VERSION ""

NS_ :

BS_:

BU_: BCM Engine FLR Gateway

BO_ 100 BCM_Status: 8 BCM
 SG_ BCM_DoorLockFL : 0|1@1+ (1,0) [0|1] "" Gateway
 SG_ BCM_DoorLockFR : 1|1@1+ (1,0) [0|1] "" Gateway
 SG_ BCM_DoorLockRL : 2|1@1+ (1,0) [0|1] "" Gateway
 SG_ BCM_DoorLockRR : 3|1@1+ (1,0) [0|1] "" Gateway
 SG_ BCM_TrunkStatus : 4|1@1+ (1,0) [0|1] "" Gateway
 SG_ BCM_HazardLight : 5|1@1+ (1,0) [0|1] "" Gateway
 SG_ BCM_LowBeam : 6|1@1+ (1,0) [0|1] "" Gateway
 SG_ BCM_HighBeam : 7|1@1+ (1,0) [0|1] "" Gateway
 SG_ BCM_BatteryVoltage : 8|12@1+ (0.01,0) [0|40.95] "V" Gateway
 SG_ BCM_InteriorTemp : 20|8@1+ (1,-40) [-40|215] "C" Gateway
 SG_ BCM_Odometer M : 32|4@1+ (1,0) [0|15] "" Gateway
 SG_ BCM_TripA m1 : 36|12@1+ (0.1,0) [0|409.5] "km" Gateway
 SG_ BCM_TripB m2 : 36|12@1+ (0.1,0) [0|409.5] "km" Gateway
 SG_ BCM_FuelLevel m3 : 36|8@1+ (0.4,0) [0|102] "L" Gateway

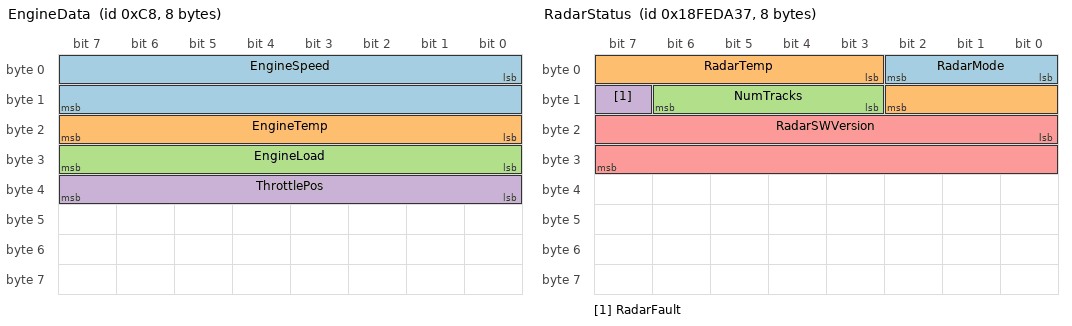
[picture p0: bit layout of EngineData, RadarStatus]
BO_ 200 EngineData: 8 Engine
 SG_ EngineSpeed : 0|16@1+ (0.25,0) [0|16383.75] "rpm" BCM
 SG_ EngineTemp : 16|8@1+ (1,-40) [-40|215] "C" BCM
 SG_ EngineLoad : 24|8@1+ (0.392157,0) [0|100] "%" BCM
 SG_ ThrottlePos : 32|8@1+ (0.392157,0) [0|100] "%" BCM

BO_ 0x18FEDA27 RadarTrack: 8 FLR
 SG_ Track_ID : 0|8@1+ (1,0) [0|255] "" Gateway
 SG_ Track_Dist : 8|12@1+ (0.1,0) [0|409.5] "m" Gateway
 SG_ Track_Vrel : 20|12@1+ (0.01,-20) [-20|20.47] "m/s" Gateway
 SG_ Track_Angle : 32|12@1+ (0.1,-90) [-90|90] "deg" Gateway
 SG_ Track_Status M : 44|2@1+ (1,0) [0|3] "" Gateway
 SG_ Track_RCS m1 : 46|8@1+ (0.5,-10) [-10|117] "dBm" Gateway
 SG_ Track_Lane m2 : 46|3@1+ (1,0) [0|7] "" Gateway
 SG_ Track_Accel m3 : 46|10@1+ (0.01,-5) [-5|5.11] "m/s2" Gateway

BO_ 0x18FEDA37 RadarStatus: 8 FLR
 SG_ RadarMode : 0|3@1+ (1,0) [0|7] "" Gateway
 SG_ RadarTemp : 3|8@1+ (1,-40) [-40|215] "C" Gateway
 SG_ NumTracks : 11|4@1+ (1,0) [0|15] "" Gateway
 SG_ RadarFault : 15|1@1+ (1,0) [0|1] "" Gateway
 SG_ RadarSWVersion : 16|16@1+ (1,0) [0|65535] "" Gateway

BO_ 0x3E8 DiagRequest: 8 Gateway
 SG_ DiagData : 0|64@1+ (1,0) [0|0] "" BCM

BO_ 0x3E9 DiagResponse: 8 BCM
 SG_ DiagData : 0|64@1+ (1,0) [0|0] "" Gateway

VAL_ 100 BCM_DoorLockFL 0 "Locked" 1 "Unlocked" ;
VAL_ 100 BCM_DoorLockFR 0 "Locked" 1 "Unlocked" ;
VAL_ 100 BCM_DoorLockRL 0 "Locked" 1 "Unlocked" ;
VAL_ 100 BCM_DoorLockRR 0 "Locked" 1 "Unlocked" ;
VAL_ 100 BCM_TrunkStatus 0 "Closed" 1 "Open" ;
VAL_ 100 BCM_HazardLight 0 "Off" 1 "On" ;
VAL_ 100 BCM_LowBeam 0 "Off" 1 "On" ;
VAL_ 100 BCM_HighBeam 0 "Off" 1 "On" ;
VAL_ 200 RadarTrack RadarMode 0 "Standby" 1 "Normal" 2 "Adaptive" 3 "Fault" ;

CM_ BO_ 100 "BCM Status Message - Contains door lock, lighting and vehicle status signals";
CM_ BO_ 200 "Engine Data Message - Contains speed, temperature and load signals";
CM_ SG_ 100 BCM_BatteryVoltage "Battery voltage in 0.01V resolution";
CM_ SG_ 100 BCM_Odometer "Multiplexer: 0=TripA, 1=TripB, 2=FuelLevel";
